# iostm8af61a8 register map
Registers are 8-bit, access not given, no defined reset value unless marked. A register's access mark holds for its fields unless they carry their own. Addresses are absolute; registers are grouped by the start of their names; [hi:lo] are bit positions; {n}, {i} and the like mark numbered series.

## CLK
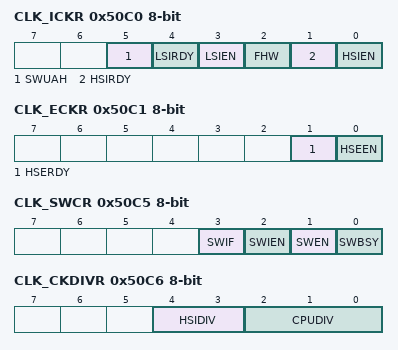
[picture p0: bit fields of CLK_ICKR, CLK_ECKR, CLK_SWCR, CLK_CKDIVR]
0x50C0 CLK_ICKR — Internal clock control register
  [5] SWUAH, [4] LSIRDY ro, [3] LSIEN, [2] FHW, [1] HSIRDY ro, [0] HSIEN
0x50C1 CLK_ECKR — External clock control register
  [1] HSERDY ro, [0] HSEEN
0x50C3 CLK_CMSR ro — Clock master status register
  [7:0] CKM
0x50C4 CLK_SWR — Clock master switch register
  [7:0] SWI
0x50C5 CLK_SWCR — Clock switch control register
  [3] SWIF, [2] SWIEN, [1] SWEN, [0] SWBSY
0x50C6 CLK_CKDIVR — Clock divider register
  [4:3] HSIDIV, [2:0] CPUDIV
0x50C7 CLK_PCKENR1 — Peripheral clock gating register 1
  [7:0] PCKEN1
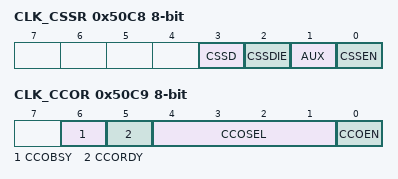
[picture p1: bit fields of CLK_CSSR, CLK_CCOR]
0x50C8 CLK_CSSR — Clock security system register
  [3] CSSD, [2] CSSDIE, [1] AUX ro, [0] CSSEN
0x50C9 CLK_CCOR — Configurable clock control register
  [6] CCOBSY, [5] CCORDY, [4:1] CCOSEL, [0] CCOEN
0x50CA CLK_PCKENR2 — Peripheral clock gating register 2
  [7:0] PCKEN2
0x50CC CLK_HSITRIMR — HSI clock calibration trimming register
  [3:0] HSITRIM
0x50CD CLK_SWIMCCR — SWIM clock control register
  [0] SWIMCLK

## WWDG
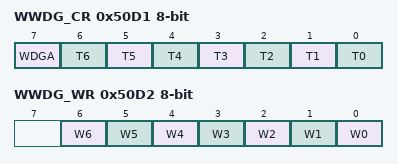
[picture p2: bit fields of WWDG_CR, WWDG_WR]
0x50D1 WWDG_CR — WWDG control register
  [7] WDGA, [n] T{n} (n=0..6)
0x50D2 WWDG_WR — WWDR window register
  [n] W{n} (n=0..6)

## IWDG
0x50E0 IWDG_KR — IWDG key register
0x50E1 IWDG_PR — IWDG prescaler register
  [2:0] PR
0x50E2 IWDG_RLR — IWDG reload register
  [7:0] RL

## AWU
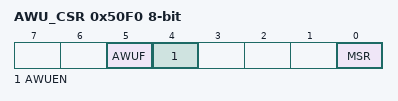
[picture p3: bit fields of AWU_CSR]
0x50F0 AWU_CSR — AWU control/status register 1
  [5] AWUF ro, [4] AWUEN, [0] MSR
0x50F1 AWU_APR — AWU asynchronous prescaler buffer register
  [5:0] APR
0x50F2 AWU_TBR — AWU timebase selection register
  [3:0] AWUTB

## SPI
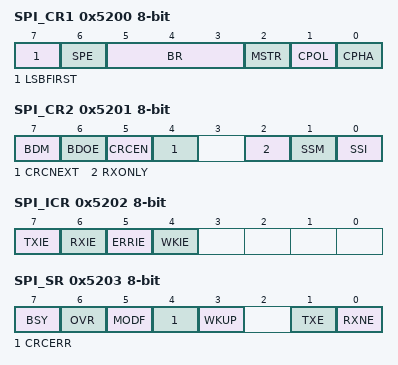
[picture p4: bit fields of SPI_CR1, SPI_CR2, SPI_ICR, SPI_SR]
0x5200 SPI_CR1 — SPI control register 1
  [7] LSBFIRST, [6] SPE, [5:3] BR, [2] MSTR, [1] CPOL, [0] CPHA
0x5201 SPI_CR2 — SPI control register 2
  [7] BDM, [6] BDOE, [5] CRCEN, [4] CRCNEXT, [2] RXONLY, [1] SSM, [0] SSI
0x5202 SPI_ICR — SPI interrupt control register
  [7] TXIE, [6] RXIE, [5] ERRIE, [4] WKIE
0x5203 SPI_SR — SPI status register
  [7] BSY ro, [6] OVR, [5] MODF, [4] CRCERR, [3] WKUP, [1] TXE ro, [0] RXNE ro
0x5204 SPI_DR — SPI data register
0x5205 SPI_CRCPR — SPI CRC polynomial register
  [7:0] CRCPOLY
0x5206 SPI_RXCRCR ro — SPI Rx CRC register
  [7:0] RXCRC
0x5207 SPI_TXCRCR ro — SPI Tx CRC register
  [7:0] TXCRC

## I2C
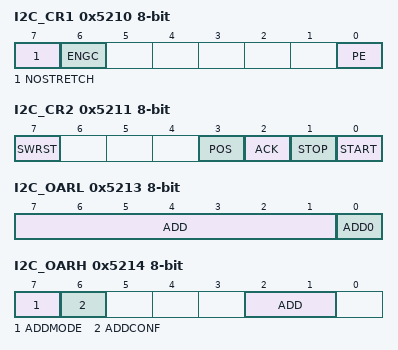
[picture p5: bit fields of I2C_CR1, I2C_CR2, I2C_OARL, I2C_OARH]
0x5210 I2C_CR1 — I2C control register 1
  [7] NOSTRETCH, [6] ENGC, [0] PE
0x5211 I2C_CR2 — I2C control register 2
  [7] SWRST, [3] POS, [2] ACK, [1] STOP, [0] START
0x5212 I2C_FREQR — I2C frequency register
  [5:0] FREQ
0x5213 I2C_OARL — I2C Own address register low
  [7:1] ADD, [0] ADD0
0x5214 I2C_OARH — I2C Own address register high
  [7] ADDMODE, [6] ADDCONF, [2:1] ADD
0x5216 I2C_DR — I2C data register
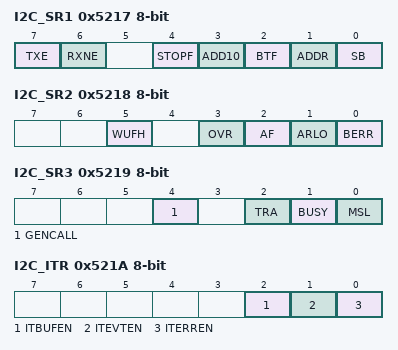
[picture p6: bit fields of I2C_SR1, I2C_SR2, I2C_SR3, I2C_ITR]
0x5217 I2C_SR1 ro — I2C status register 1
  [7] TXE, [6] RXNE, [4] STOPF, [3] ADD10, [2] BTF, [1] ADDR, [0] SB
0x5218 I2C_SR2 ro — I2C status register 2
  [5] WUFH, [3] OVR, [2] AF, [1] ARLO, [0] BERR
0x5219 I2C_SR3 ro — I2C status register 3
  [4] GENCALL, [2] TRA, [1] BUSY, [0] MSL
0x521A I2C_ITR — I2C interrupt control register
  [2] ITBUFEN, [1] ITEVTEN, [0] ITERREN
0x521B I2C_CCRL — I2C clock control register low
  [7:0] CCR
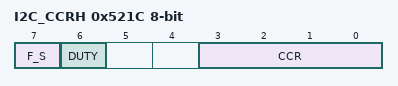
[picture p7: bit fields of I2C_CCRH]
0x521C I2C_CCRH — I2C clock control register high
  [7] F_S, [6] DUTY, [3:0] CCR
0x521D I2C_TRISER — I2C TRISE register
  [5:0] TRISE

## USART
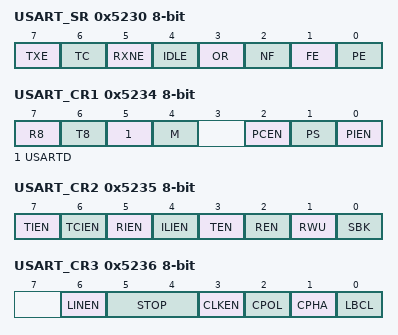
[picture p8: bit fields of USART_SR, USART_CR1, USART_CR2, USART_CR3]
0x5230 USART_SR ro — USART status register
  [7] TXE, [6] TC, [5] RXNE, [4] IDLE, [3] OR, [2] NF, [1] FE, [0] PE
0x5231 USART_DR — USART data register
0x5232 USART_BRR1 — USART baud rate register 1
  [7:0] USART_DIV
0x5233 USART_BRR2 — USART baud rate register 2
  [7:0] USART_DIV
0x5234 USART_CR1 — USART control register 1
  [7] R8, [6] T8, [5] USARTD, [4] M, [2] PCEN, [1] PS, [0] PIEN
0x5235 USART_CR2 — USART control register 2
  [7] TIEN, [6] TCIEN, [5] RIEN, [4] ILIEN, [3] TEN, [2] REN, [1] RWU, [0] SBK
0x5236 USART_CR3 — USART control register 3
  [6] LINEN, [5:4] STOP, [3] CLKEN, [2] CPOL, [1] CPHA, [0] LBCL
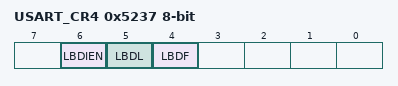
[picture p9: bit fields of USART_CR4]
0x5237 USART_CR4 — USART control register 4
  [6] LBDIEN, [5] LBDL, [4] LBDF
